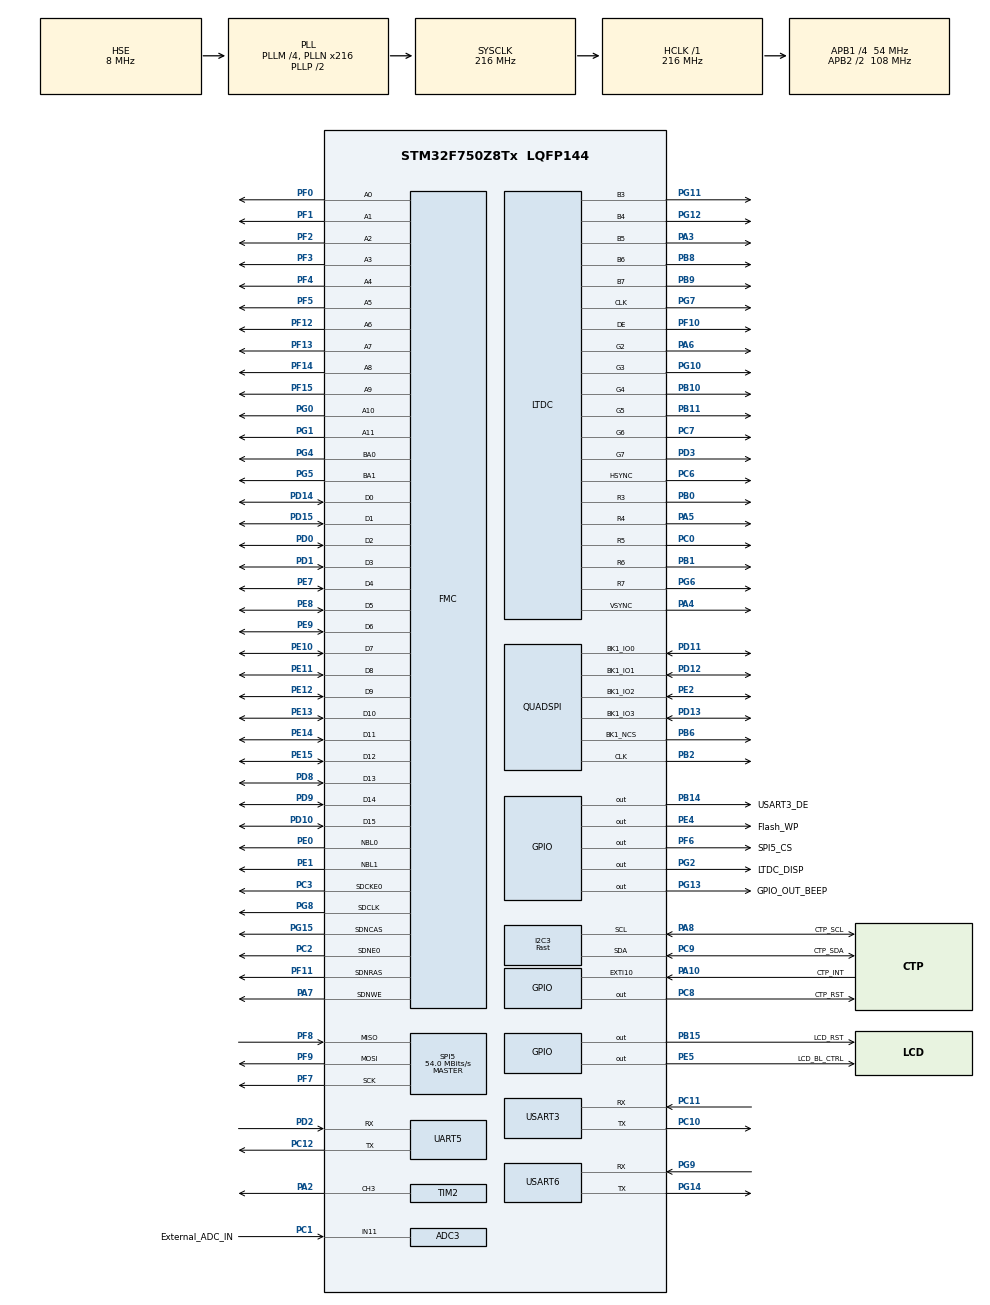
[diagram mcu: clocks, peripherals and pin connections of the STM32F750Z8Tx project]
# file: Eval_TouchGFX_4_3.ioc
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ADC3.Channel-1\#ChannelRegularConversion=ADC_CHANNEL_11
ADC3.NbrOfConversionFlag=1
ADC3.Rank-1\#ChannelRegularConversion=1
ADC3.SamplingTime-1\#ChannelRegularConversion=ADC_SAMPLETIME_3CYCLES
CORTEX_M7.ART_ACCLERATOR_ENABLE=1
CORTEX_M7.AccessPermission-Cortex_Memory_Protection_Unit_Region0_Settings=MPU_REGION_FULL_ACCESS
CORTEX_M7.BaseAddress-Cortex_Memory_Protection_Unit_Region0_Settings=0xC0000000
CORTEX_M7.CPU_DCache=Enabled
CORTEX_M7.CPU_ICache=Enabled
CORTEX_M7.DisableExec-Cortex_Memory_Protection_Unit_Region0_Settings=MPU_INSTRUCTION_ACCESS_DISABLE
CORTEX_M7.Enable-Cortex_Memory_Protection_Unit_Region0_Settings=MPU_REGION_ENABLE
CORTEX_M7.IsCacheable-Cortex_Memory_Protection_Unit_Region0_Settings=MPU_ACCESS_CACHEABLE
CORTEX_M7.IsShareable-Cortex_Memory_Protection_Unit_Region0_Settings=MPU_ACCESS_NOT_SHAREABLE
CORTEX_M7.MPU_Control=MPU_PRIVILEGED_DEFAULT
CORTEX_M7.Size-Cortex_Memory_Protection_Unit_Region0_Settings=MPU_REGION_SIZE_8MB
DMA2D.ColorMode=DMA2D_OUTPUT_RGB565
Dma.MEMTOMEM.1.Direction=DMA_MEMORY_TO_MEMORY
Dma.MEMTOMEM.1.FIFOMode=DMA_FIFOMODE_ENABLE
Dma.MEMTOMEM.1.FIFOThreshold=DMA_FIFO_THRESHOLD_FULL
Dma.MEMTOMEM.1.Instance=DMA2_Stream0
Dma.MEMTOMEM.1.MemBurst=DMA_MBURST_SINGLE
Dma.MEMTOMEM.1.MemDataAlignment=DMA_MDATAALIGN_BYTE
Dma.MEMTOMEM.1.MemInc=DMA_MINC_ENABLE
Dma.MEMTOMEM.1.Mode=DMA_NORMAL
Dma.MEMTOMEM.1.PeriphBurst=DMA_PBURST_SINGLE
Dma.MEMTOMEM.1.PeriphDataAlignment=DMA_PDATAALIGN_BYTE
Dma.MEMTOMEM.1.PeriphInc=DMA_PINC_ENABLE
Dma.MEMTOMEM.1.Priority=DMA_PRIORITY_LOW
Dma.QUADSPI.0.Direction=DMA_PERIPH_TO_MEMORY
Dma.QUADSPI.0.FIFOMode=DMA_FIFOMODE_DISABLE
Dma.QUADSPI.0.Instance=DMA2_Stream7
Dma.QUADSPI.0.MemDataAlignment=DMA_MDATAALIGN_BYTE
Dma.QUADSPI.0.MemInc=DMA_MINC_ENABLE
Dma.QUADSPI.0.Mode=DMA_NORMAL
Dma.QUADSPI.0.PeriphDataAlignment=DMA_PDATAALIGN_BYTE
Dma.QUADSPI.0.PeriphInc=DMA_PINC_DISABLE
Dma.QUADSPI.0.Priority=DMA_PRIORITY_HIGH
Dma.Request0=QUADSPI
Dma.Request1=MEMTOMEM
Dma.Request2=SPI5_RX
Dma.Request3=SPI5_TX
Dma.Request4=USART3_RX
Dma.Request5=USART3_TX
Dma.SPI5_RX.2.Direction=DMA_PERIPH_TO_MEMORY
Dma.SPI5_RX.2.FIFOMode=DMA_FIFOMODE_DISABLE
Dma.SPI5_RX.2.Instance=DMA2_Stream3
Dma.SPI5_RX.2.MemDataAlignment=DMA_MDATAALIGN_BYTE
Dma.SPI5_RX.2.MemInc=DMA_MINC_ENABLE
Dma.SPI5_RX.2.Mode=DMA_NORMAL
Dma.SPI5_RX.2.PeriphDataAlignment=DMA_PDATAALIGN_BYTE
Dma.SPI5_RX.2.PeriphInc=DMA_PINC_DISABLE
Dma.SPI5_RX.2.Priority=DMA_PRIORITY_LOW
Dma.SPI5_TX.3.Direction=DMA_MEMORY_TO_PERIPH
Dma.SPI5_TX.3.FIFOMode=DMA_FIFOMODE_DISABLE
Dma.SPI5_TX.3.Instance=DMA2_Stream4
Dma.SPI5_TX.3.MemDataAlignment=DMA_MDATAALIGN_BYTE
Dma.SPI5_TX.3.MemInc=DMA_MINC_ENABLE
Dma.SPI5_TX.3.Mode=DMA_NORMAL
Dma.SPI5_TX.3.PeriphDataAlignment=DMA_PDATAALIGN_BYTE
Dma.SPI5_TX.3.PeriphInc=DMA_PINC_DISABLE
Dma.SPI5_TX.3.Priority=DMA_PRIORITY_LOW
Dma.USART3_RX.4.Direction=DMA_PERIPH_TO_MEMORY
Dma.USART3_RX.4.FIFOMode=DMA_FIFOMODE_DISABLE
Dma.USART3_RX.4.Instance=DMA1_Stream1
Dma.USART3_RX.4.MemDataAlignment=DMA_MDATAALIGN_BYTE
Dma.USART3_RX.4.MemInc=DMA_MINC_ENABLE
Dma.USART3_RX.4.Mode=DMA_NORMAL
Dma.USART3_RX.4.PeriphDataAlignment=DMA_PDATAALIGN_BYTE
Dma.USART3_RX.4.PeriphInc=DMA_PINC_DISABLE
Dma.USART3_RX.4.Priority=DMA_PRIORITY_HIGH
Dma.USART3_TX.5.Direction=DMA_MEMORY_TO_PERIPH
Dma.USART3_TX.5.FIFOMode=DMA_FIFOMODE_DISABLE
Dma.USART3_TX.5.Instance=DMA1_Stream3
Dma.USART3_TX.5.MemDataAlignment=DMA_MDATAALIGN_BYTE
Dma.USART3_TX.5.MemInc=DMA_MINC_ENABLE
Dma.USART3_TX.5.Mode=DMA_NORMAL
Dma.USART3_TX.5.PeriphDataAlignment=DMA_PDATAALIGN_BYTE
Dma.USART3_TX.5.PeriphInc=DMA_PINC_DISABLE
Dma.USART3_TX.5.Priority=DMA_PRIORITY_LOW
FMC.CASLatency1=FMC_SDRAM_CAS_LATENCY_3
FMC.ExitSelfRefreshDelay1=7
FMC.LoadToActiveDelay1=2
FMC.RCDDelay1=2
FMC.RPDelay1=2
FMC.RPDelay2=2
FMC.ReadBurst1=FMC_SDRAM_RBURST_ENABLE
FMC.ReadBurst2=FMC_SDRAM_RBURST_ENABLE
FMC.RowCycleDelay1=7
FMC.RowCycleDelay2=7
FMC.SDClockPeriod1=FMC_SDRAM_CLOCK_PERIOD_2
FMC.SDClockPeriod2=FMC_SDRAM_CLOCK_PERIOD_2
FMC.SelfRefreshTime1=4
FMC.WriteRecoveryTime1=3
FREERTOS.INCLUDE_vTaskDelayUntil=1
FREERTOS.INCLUDE_xSemaphoreGetMutexHolder=1
FREERTOS.Tasks01=TouchGFXTask,24,8192,TouchGFX_Task,As weak,NULL,Dynamic,NULL,NULL
FREERTOS.configTOTAL_HEAP_SIZE=65536
FREERTOS.configUSE_APPLICATION_TASK_TAG=1
FREERTOS.configUSE_IDLE_HOOK=1
FREERTOS.configUSE_TICK_HOOK=0
I2C3.I2C_Speed_Mode=I2C_Fast
I2C3.Timing=0x6000030D
LTDC.ActiveH=272
LTDC.ActiveW=480
LTDC.Alpha_L0=255
LTDC.DEPolarity=LTDC_DEPOLARITY_AH
LTDC.FBStartAdress_L0=0xC0700000
LTDC.HBP=40
LTDC.HFP=8
LTDC.HSync=4
LTDC.ImageHeight_L0=272
LTDC.ImageWidth_L0=480
LTDC.Layers=0
LTDC.PCPolarity=LTDC_PCPOLARITY_IIPC
LTDC.PixelFormat_L0=LTDC_PIXEL_FORMAT_RGB565
LTDC.VBP=8
LTDC.VFP=8
LTDC.VSync=4
LTDC.WindowX1_L0=480
LTDC.WindowY1_L0=272
Mcu.Family=STM32F7
Mcu.Name=STM32F750Z8Tx
Mcu.Package=LQFP144
NVIC.DMA1_Stream1_IRQn=true\:5\:0\:true\:false\:true\:true\:false\:true
NVIC.DMA1_Stream3_IRQn=true\:5\:0\:true\:false\:true\:true\:false\:true
NVIC.DMA2_Stream3_IRQn=true\:5\:0\:true\:false\:true\:true\:false\:true
NVIC.DMA2_Stream4_IRQn=true\:5\:0\:true\:false\:true\:true\:false\:true
NVIC.DMA2_Stream7_IRQn=true\:5\:0\:true\:false\:true\:true\:false\:true
NVIC.I2C3_ER_IRQn=true\:5\:0\:true\:false\:true\:true\:true\:true
NVIC.I2C3_EV_IRQn=true\:5\:0\:true\:false\:true\:true\:true\:true
NVIC.LTDC_ER_IRQn=true\:5\:0\:true\:false\:true\:true\:true\:true
NVIC.LTDC_IRQn=true\:5\:0\:true\:false\:true\:true\:true\:true
NVIC.PriorityGroup=NVIC_PRIORITYGROUP_4
NVIC.TIM5_IRQn=true\:0\:0\:false\:false\:true\:false\:false\:true
NVIC.TIM7_IRQn=true\:5\:0\:true\:false\:true\:false\:true\:true
NVIC.TimeBase=TIM5_IRQn
NVIC.TimeBaseIP=TIM5
NVIC.USART3_IRQn=true\:5\:0\:true\:false\:true\:true\:true\:true
PA1.Signal=LTDC_R2
PA10.GPIO_Label=CTP_INT
PA10.Signal=GPXTI10
PA13.Mode=Serial_Wire
PA13.Signal=SYS_JTMS-SWDIO
PA14.Mode=Serial_Wire
PA14.Signal=SYS_JTCK-SWCLK
PA2.Signal=S_TIM2_CH3
PA3.GPIO_Speed=GPIO_SPEED_FREQ_VERY_HIGH
PA3.Mode=RGB565
PA3.Signal=LTDC_B5
PA4.GPIO_Speed=GPIO_SPEED_FREQ_VERY_HIGH
PA4.Mode=RGB565
PA4.Signal=LTDC_VSYNC
PA5.GPIO_Speed=GPIO_SPEED_FREQ_VERY_HIGH
PA5.Mode=RGB565
PA5.Signal=LTDC_R4
PA6.GPIO_Speed=GPIO_SPEED_FREQ_VERY_HIGH
PA6.Mode=RGB565
PA6.Signal=LTDC_G2
PA7.Signal=FMC_SDNWE
PA8.GPIO_Label=CTP_SCL
PA8.Mode=I2C
PA8.Signal=I2C3_SCL
PB0.GPIO_Speed=GPIO_SPEED_FREQ_VERY_HIGH
PB0.Mode=RGB565
PB0.Signal=LTDC_R3
PB1.GPIO_Speed=GPIO_SPEED_FREQ_VERY_HIGH
PB1.Mode=RGB565
PB1.Signal=LTDC_R6
PB10.GPIO_Speed=GPIO_SPEED_FREQ_VERY_HIGH
PB10.Mode=RGB565
PB10.Signal=LTDC_G4
PB11.GPIO_Speed=GPIO_SPEED_FREQ_VERY_HIGH
PB11.Mode=RGB565
PB11.Signal=LTDC_G5
PB13.Signal=CAN2_TX
PB14.GPIO_Label=USART3_DE
PB14.Signal=GPIO_Output
PB15.GPIO_Label=LCD_RST
PB15.Signal=GPIO_Output
PB2.Mode=Single Bank 1
PB2.Signal=QUADSPI_CLK
PB6.Mode=Single Bank 1
PB6.Signal=QUADSPI_BK1_NCS
PB8.GPIO_Speed=GPIO_SPEED_FREQ_VERY_HIGH
PB8.Mode=RGB565
PB8.Signal=LTDC_B6
PB9.GPIO_Speed=GPIO_SPEED_FREQ_VERY_HIGH
PB9.Mode=RGB565
PB9.Signal=LTDC_B7
PC0.GPIO_Speed=GPIO_SPEED_FREQ_VERY_HIGH
PC0.Mode=RGB565
PC0.Signal=LTDC_R5
PC1.GPIO_Label=External_ADC_IN
PC1.Signal=ADCx_IN11
PC10.Mode=Asynchronous
PC10.Signal=USART3_TX
PC11.Mode=Asynchronous
PC11.Signal=USART3_RX
PC12.Mode=Asynchronous
PC12.Signal=UART5_TX
PC14/OSC32_IN.Mode=LSE-External-Oscillator
PC14/OSC32_IN.Signal=RCC_OSC32_IN
PC15/OSC32_OUT.Mode=LSE-External-Oscillator
PC15/OSC32_OUT.Signal=RCC_OSC32_OUT
PC2.Mode=SdramChipSelect1_1
PC2.Signal=FMC_SDNE0
PC3.Mode=SdramChipSelect1_1
PC3.Signal=FMC_SDCKE0
PC6.GPIO_Speed=GPIO_SPEED_FREQ_VERY_HIGH
PC6.Mode=RGB565
PC6.Signal=LTDC_HSYNC
PC7.GPIO_Speed=GPIO_SPEED_FREQ_VERY_HIGH
PC7.Mode=RGB565
PC7.Signal=LTDC_G6
PC8.GPIO_Label=CTP_RST
PC8.PinState=GPIO_PIN_SET
PC8.Signal=GPIO_Output
PC9.GPIO_Label=CTP_SDA
PC9.Mode=I2C
PC9.Signal=I2C3_SDA
PD0.Signal=FMC_D2_DA2
PD1.Signal=FMC_D3_DA3
PD10.Signal=FMC_D15_DA15
PD11.Mode=Single Bank 1
PD11.Signal=QUADSPI_BK1_IO0
PD12.Mode=Single Bank 1
PD12.Signal=QUADSPI_BK1_IO1
PD13.Mode=Single Bank 1
PD13.Signal=QUADSPI_BK1_IO3
PD14.Signal=FMC_D0_DA0
PD15.Signal=FMC_D1_DA1
PD2.Mode=Asynchronous
PD2.Signal=UART5_RX
PD3.GPIO_Speed=GPIO_SPEED_FREQ_VERY_HIGH
PD3.Mode=RGB565
PD3.Signal=LTDC_G7
PD6.Signal=LTDC_B2
PD8.Signal=FMC_D13_DA13
PD9.Signal=FMC_D14_DA14
PE0.Signal=FMC_NBL0
PE1.Signal=FMC_NBL1
PE10.Signal=FMC_D7_DA7
PE11.Signal=FMC_D8_DA8
PE12.Signal=FMC_D9_DA9
PE13.Signal=FMC_D10_DA10
PE14.Signal=FMC_D11_DA11
PE15.Signal=FMC_D12_DA12
PE2.Mode=Single Bank 1
PE2.Signal=QUADSPI_BK1_IO2
PE4.GPIO_Label=Flash_WP
PE4.PinState=GPIO_PIN_SET
PE4.Signal=GPIO_Output
PE5.GPIO_Label=LCD_BL_CTRL
PE5.PinState=GPIO_PIN_SET
PE5.Signal=GPIO_Output
PE7.Signal=FMC_D4_DA4
PE8.Signal=FMC_D5_DA5
PE9.Signal=FMC_D6_DA6
PF0.Signal=FMC_A0
PF1.Signal=FMC_A1
PF10.GPIO_PuPd=GPIO_NOPULL
PF10.GPIO_Speed=GPIO_SPEED_FREQ_VERY_HIGH
PF10.Mode=RGB565
PF10.Signal=LTDC_DE
PF11.Signal=FMC_SDNRAS
PF12.Signal=FMC_A6
PF13.Signal=FMC_A7
PF14.Signal=FMC_A8
PF15.Signal=FMC_A9
PF2.Signal=FMC_A2
PF3.Signal=FMC_A3
PF4.Signal=FMC_A4
PF5.Signal=FMC_A5
PF6.GPIO_Label=SPI5_CS
PF6.GPIO_Speed=GPIO_SPEED_FREQ_HIGH
PF6.Signal=GPIO_Output
PF7.Mode=Full_Duplex_Master
PF7.Signal=SPI5_SCK
PF8.Mode=Full_Duplex_Master
PF8.Signal=SPI5_MISO
PF9.Mode=Full_Duplex_Master
PF9.Signal=SPI5_MOSI
PG0.Signal=FMC_A10
PG1.Signal=FMC_A11
PG10.GPIO_Speed=GPIO_SPEED_FREQ_VERY_HIGH
PG10.Mode=RGB565
PG10.Signal=LTDC_G3
PG11.GPIO_Speed=GPIO_SPEED_FREQ_VERY_HIGH
PG11.Mode=RGB565
PG11.Signal=LTDC_B3
PG12.GPIO_Speed=GPIO_SPEED_FREQ_VERY_HIGH
PG12.Mode=RGB565
PG12.Signal=LTDC_B4
PG13.GPIO_Label=GPIO_OUT_BEEP
PG13.Signal=GPIO_Output
PG14.Mode=Asynchronous
PG14.Signal=USART6_TX
PG15.Signal=FMC_SDNCAS
PG2.GPIO_Label=LTDC_DISP
PG2.Signal=GPIO_Output
PG4.Signal=FMC_A14_BA0
PG5.Signal=FMC_A15_BA1
PG6.GPIO_Speed=GPIO_SPEED_FREQ_VERY_HIGH
PG6.Mode=RGB565
PG6.Signal=LTDC_R7
PG7.GPIO_Speed=GPIO_SPEED_FREQ_VERY_HIGH
PG7.Mode=RGB565
PG7.Signal=LTDC_CLK
PG8.Signal=FMC_SDCLK
PG9.Mode=Asynchronous
PG9.Signal=USART6_RX
PH0/OSC_IN.Mode=HSE-External-Oscillator
PH0/OSC_IN.Signal=RCC_OSC_IN
PH1/OSC_OUT.Mode=HSE-External-Oscillator
PH1/OSC_OUT.Signal=RCC_OSC_OUT
ProjectManager.HeapSize=0x1000
ProjectManager.StackSize=0x1000
ProjectManager.TargetToolchain=STM32CubeIDE
QUADSPI.ChipSelectHighTime=QSPI_CS_HIGH_TIME_2_CYCLE
QUADSPI.ClockPrescaler=3
QUADSPI.FifoThreshold=4
QUADSPI.FlashSize=16
QUADSPI.SampleShifting=QSPI_SAMPLE_SHIFTING_HALFCYCLE
RCC.AHBFreq_Value=216000000
RCC.APB1CLKDivider=RCC_HCLK_DIV4
RCC.APB1Freq_Value=54000000
RCC.APB1TimFreq_Value=108000000
RCC.APB2CLKDivider=RCC_HCLK_DIV2
RCC.APB2Freq_Value=108000000
RCC.APB2TimFreq_Value=216000000
RCC.CortexFreq_Value=216000000
RCC.HCLKFreq_Value=216000000
RCC.HSE_VALUE=8000000
RCC.HSI_VALUE=16000000
RCC.LSE_Drive_Capability=RCC_LSEDRIVE_HIGH
RCC.PLLM=4
RCC.PLLN=216
RCC.PLLSAIN=54
RCC.PLLSAIR=3
RCC.PLLSAIRDiv=RCC_PLLSAIDIVR_4
RCC.PLLSourceVirtual=RCC_PLLSOURCE_HSE
RCC.RTCClockSelection=RCC_RTCCLKSOURCE_LSE
RCC.SYSCLKFreq_VALUE=216000000
RCC.SYSCLKSource=RCC_SYSCLKSOURCE_PLLCLK
RCC.USBFreq_Value=216000000
RCC.VCOOutputFreq_Value=432000000
RTC.Format=RTC_FORMAT_BIN
RTC.WeekDay=RTC_WEEKDAY_FRIDAY
RTC.Year=21
SH.ADCx_IN11.0=ADC3_IN11,IN11
SH.FMC_A0.0=FMC_A0,12b-sda1
SH.FMC_A1.0=FMC_A1,12b-sda1
SH.FMC_A10.0=FMC_A10,12b-sda1
SH.FMC_A11.0=FMC_A11,12b-sda1
SH.FMC_A14_BA0.0=FMC_BA0,FourSdramBanks1
SH.FMC_A15_BA1.0=FMC_BA1,FourSdramBanks1
SH.FMC_A2.0=FMC_A2,12b-sda1
SH.FMC_A3.0=FMC_A3,12b-sda1
SH.FMC_A4.0=FMC_A4,12b-sda1
SH.FMC_A5.0=FMC_A5,12b-sda1
SH.FMC_A6.0=FMC_A6,12b-sda1
SH.FMC_A7.0=FMC_A7,12b-sda1
SH.FMC_A8.0=FMC_A8,12b-sda1
SH.FMC_A9.0=FMC_A9,12b-sda1
SH.FMC_D0_DA0.0=FMC_D0,sd-16b-d1
SH.FMC_D10_DA10.0=FMC_D10,sd-16b-d1
SH.FMC_D11_DA11.0=FMC_D11,sd-16b-d1
SH.FMC_D12_DA12.0=FMC_D12,sd-16b-d1
SH.FMC_D13_DA13.0=FMC_D13,sd-16b-d1
SH.FMC_D14_DA14.0=FMC_D14,sd-16b-d1
SH.FMC_D15_DA15.0=FMC_D15,sd-16b-d1
SH.FMC_D1_DA1.0=FMC_D1,sd-16b-d1
SH.FMC_D2_DA2.0=FMC_D2,sd-16b-d1
SH.FMC_D3_DA3.0=FMC_D3,sd-16b-d1
SH.FMC_D4_DA4.0=FMC_D4,sd-16b-d1
SH.FMC_D5_DA5.0=FMC_D5,sd-16b-d1
SH.FMC_D6_DA6.0=FMC_D6,sd-16b-d1
SH.FMC_D7_DA7.0=FMC_D7,sd-16b-d1
SH.FMC_D8_DA8.0=FMC_D8,sd-16b-d1
SH.FMC_D9_DA9.0=FMC_D9,sd-16b-d1
SH.FMC_NBL0.0=FMC_NBL0,Sd2ByteEnable1
SH.FMC_NBL1.0=FMC_NBL1,Sd2ByteEnable1
SH.FMC_SDCLK.0=FMC_SDCLK,12b-sda1
SH.FMC_SDNCAS.0=FMC_SDNCAS,12b-sda1
SH.FMC_SDNRAS.0=FMC_SDNRAS,12b-sda1
SH.FMC_SDNWE.0=FMC_SDNWE,12b-sda1
SH.S_TIM2_CH3.0=TIM2_CH3,PWM Generation3 CH3
SPI5.CalculateBaudRate=54.0 MBits/s
SPI5.DataSize=SPI_DATASIZE_8BIT
SPI5.Direction=SPI_DIRECTION_2LINES
SPI5.Mode=SPI_MODE_MASTER
SPI5.NSSPMode=SPI_NSS_PULSE_DISABLE
SPI5.VirtualType=VM_MASTER
STMicroelectronics.X-CUBE-TOUCHGFX.4.16.0.ApplicationCcGraphicsJjApplication=TouchGFXOoGenerator
STMicroelectronics.X-CUBE-TOUCHGFX.4.16.0.tgfx_address1=0xc0700000
STMicroelectronics.X-CUBE-TOUCHGFX.4.16.0.tgfx_address2=0xc073FC00
STMicroelectronics.X-CUBE-TOUCHGFX.4.16.0.tgfx_buffering_strategy=Double
STMicroelectronics.X-CUBE-TOUCHGFX.4.16.0.tgfx_custom_height=128
STMicroelectronics.X-CUBE-TOUCHGFX.4.16.0.tgfx_display_interface=disp_ltdc
STMicroelectronics.X-CUBE-TOUCHGFX.4.16.0.tgfx_hardware_accelerator=dma_2d
STMicroelectronics.X-CUBE-TOUCHGFX.4.16.0.tgfx_location=By Address
STMicroelectronics.X-CUBE-TOUCHGFX.4.16.0.tgfx_vsync=vsync_ltdc
TIM2.AutoReloadPreload=TIM_AUTORELOAD_PRELOAD_ENABLE
TIM2.Channel-PWM\ Generation3\ CH3=TIM_CHANNEL_3
TIM2.Period=99
TIM2.Prescaler=72
TIM7.Period=0
USART3.VirtualMode-Asynchronous=VM_ASYNC
USART6.VirtualMode-Asynchronous=VM_ASYNC
VP_CRC_VS_CRC.Mode=CRC_Activate
VP_DMA2D_VS_DMA2D.Mode=DMA2D_Activate
VP_FREERTOS_VS_CMSIS_V2.Mode=CMSIS_V2
VP_RTC_VS_RTC_Activate.Mode=RTC_Enabled
VP_RTC_VS_RTC_Calendar.Mode=RTC_Calendar
VP_STMicroelectronics.X-CUBE-TOUCHGFX_VS_GraphicsJjApplication_4.16.0.Mode=GraphicsJjApplication
VP_SYS_VS_tim5.Mode=TIM5
VP_TIM7_VS_ClockSourceINT.Mode=Enable_Timer
board=custom

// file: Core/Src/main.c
/* USER CODE BEGIN Header */
/**
  ******************************************************************************
  * @file           : main.c
  * @brief          : Main program body
  ******************************************************************************
  * @attention
  *
  * <h2><center>&copy; Copyright (c) 2020 STMicroelectronics.
  * All rights reserved.</center></h2>
  *
  * This software component is licensed by ST under Ultimate Liberty license
  * SLA0044, the "License"; You may not use this file except in compliance with
  * the License. You may obtain a copy of the License at:
  *                             www.st.com/SLA0044
  *
  ******************************************************************************
  */
/* USER CODE END Header */
#include "main.h"
#include "cmsis_os.h"
#include "app_touchgfx.h"

/* USER CODE BEGIN Includes */
#include "stm32f7508_discovery_sdram.h"
/* USER CODE END Includes */

/* USER CODE BEGIN PD */
#define ADDR_DISPLAY_MEM    ((uint32_t)0xC0700000)
/* USER CODE END PD */

ADC_HandleTypeDef hadc3;

CRC_HandleTypeDef hcrc;

DMA2D_HandleTypeDef hdma2d;

I2C_HandleTypeDef hi2c3;

LTDC_HandleTypeDef hltdc;

QSPI_HandleTypeDef hqspi;
DMA_HandleTypeDef hdma_quadspi;

RTC_HandleTypeDef hrtc;

SPI_HandleTypeDef hspi5;
DMA_HandleTypeDef hdma_spi5_rx;
DMA_HandleTypeDef hdma_spi5_tx;

TIM_HandleTypeDef htim2;
TIM_HandleTypeDef htim7;

UART_HandleTypeDef huart5;
UART_HandleTypeDef huart3;
UART_HandleTypeDef huart6;
DMA_HandleTypeDef hdma_usart3_rx;
DMA_HandleTypeDef hdma_usart3_tx;

DMA_HandleTypeDef hdma_memtomem_dma2_stream0;
SDRAM_HandleTypeDef hsdram1;

/* Definitions for TouchGFXTask */
osThreadId_t TouchGFXTaskHandle;
const osThreadAttr_t TouchGFXTask_attributes = {
  .name = "TouchGFXTask",
  .priority = (osPriority_t) osPriorityNormal,
  .stack_size = 8192 * 4
};

void SystemClock_Config(void);
static void MPU_Config(void);
static void MX_GPIO_Init(void);
static void MX_DMA_Init(void);
static void MX_QUADSPI_Init(void);
static void MX_DMA2D_Init(void);
static void MX_LTDC_Init(void);
static void MX_CRC_Init(void);
static void MX_FMC_Init(void);
static void MX_TIM7_Init(void);
static void MX_USART3_UART_Init(void);
static void MX_ADC3_Init(void);
static void MX_SPI5_Init(void);
static void MX_USART6_UART_Init(void);
static void MX_UART5_Init(void);
static void MX_I2C3_Init(void);
static void MX_TIM2_Init(void);
static void MX_RTC_Init(void);
void TouchGFX_Task(void *argument);

/* USER CODE BEGIN PFP */
void MX_SDRAM_InitEx(void);
/* USER CODE END PFP */

/* USER CODE BEGIN 0 */
void Debug()
{
  while(1){

    HAL_Delay(500);

    HAL_GPIO_WritePin(GPIOE, LCD_BL_CTRL_Pin, GPIO_PIN_SET);

    HAL_Delay(500);

    HAL_GPIO_WritePin(GPIOE, LCD_BL_CTRL_Pin, GPIO_PIN_RESET);

  }

}

void HW_VerifySDRAM(void)
{
  volatile uint32_t *pBuf = (uint32_t*) 0xc0000000;

  static uint32_t failCnt = 0;
  uint32_t cnt = 8 * 1024 * 1024 / 4;

  for (uint32_t i = 0; i < cnt; i++)
    *(pBuf++) = i;

  pBuf = (uint32_t*) 0xc0000000;

  for (uint32_t i = 0; i < cnt; i++) {

    if (*(pBuf++) != i) {

      failCnt++;
      HAL_GPIO_WritePin(GPIOE, LCD_BL_CTRL_Pin, GPIO_PIN_SET);
      while(1);
    }
  }

}

/* USER CODE END 0 */

int main(void)
{

  /* MPU Configuration--------------------------------------------------------*/
  MPU_Config();

  /* Enable I-Cache---------------------------------------------------------*/
  SCB_EnableICache();

  /* Enable D-Cache---------------------------------------------------------*/
  SCB_EnableDCache();

  /* MCU Configuration--------------------------------------------------------*/

  /* Reset of all peripherals, Initializes the Flash interface and the Systick. */
  HAL_Init();

  /* Configure the system clock */
  SystemClock_Config();

  /* Initialize all configured peripherals */
  MX_GPIO_Init();
  MX_DMA_Init();
  MX_QUADSPI_Init();
  MX_DMA2D_Init();
  MX_LTDC_Init();
  MX_CRC_Init();
  MX_FMC_Init();
  MX_TIM7_Init();
  MX_USART3_UART_Init();
  MX_ADC3_Init();
  MX_SPI5_Init();
  MX_USART6_UART_Init();
  MX_UART5_Init();
  MX_I2C3_Init();
  MX_TIM2_Init();
  MX_RTC_Init();
  MX_TouchGFX_Init();

  /* Init scheduler */
  osKernelInitialize();

  /* Create the thread(s) */
  /* creation of TouchGFXTask */
  TouchGFXTaskHandle = osThreadNew(TouchGFX_Task, NULL, &TouchGFXTask_attributes);

  /* Start scheduler */
  osKernelStart();

  /* We should never get here as control is now taken by the scheduler */
  /* Infinite loop */
  while (1)
  {

  }
}

void SystemClock_Config(void)
{
  RCC_OscInitTypeDef RCC_OscInitStruct = {0};
  RCC_ClkInitTypeDef RCC_ClkInitStruct = {0};
  RCC_PeriphCLKInitTypeDef PeriphClkInitStruct = {0};

  /** Configure LSE Drive Capability
  */
  HAL_PWR_EnableBkUpAccess();
  __HAL_RCC_LSEDRIVE_CONFIG(RCC_LSEDRIVE_HIGH);
  /** Configure the main internal regulator output voltage
  */
  __HAL_RCC_PWR_CLK_ENABLE();
  __HAL_PWR_VOLTAGESCALING_CONFIG(PWR_REGULATOR_VOLTAGE_SCALE1);
  /** Initializes the RCC Oscillators according to the specified parameters
  * in the RCC_OscInitTypeDef structure.
  */
  RCC_OscInitStruct.OscillatorType = RCC_OSCILLATORTYPE_HSE|RCC_OSCILLATORTYPE_LSE;
  RCC_OscInitStruct.HSEState = RCC_HSE_ON;
  RCC_OscInitStruct.LSEState = RCC_LSE_ON;
  RCC_OscInitStruct.PLL.PLLState = RCC_PLL_ON;
  RCC_OscInitStruct.PLL.PLLSource = RCC_PLLSOURCE_HSE;
  RCC_OscInitStruct.PLL.PLLM = 4;
  RCC_OscInitStruct.PLL.PLLN = 216;
  RCC_OscInitStruct.PLL.PLLP = RCC_PLLP_DIV2;
  RCC_OscInitStruct.PLL.PLLQ = 2;
  if (HAL_RCC_OscConfig(&RCC_OscInitStruct) != HAL_OK)
  {
    Error_Handler();
  }
  /** Activate the Over-Drive mode
  */
  if (HAL_PWREx_EnableOverDrive() != HAL_OK)
  {
    Error_Handler();
  }
  /** Initializes the CPU, AHB and APB buses clocks
  */
  RCC_ClkInitStruct.ClockType = RCC_CLOCKTYPE_HCLK|RCC_CLOCKTYPE_SYSCLK
                              |RCC_CLOCKTYPE_PCLK1|RCC_CLOCKTYPE_PCLK2;
  RCC_ClkInitStruct.SYSCLKSource = RCC_SYSCLKSOURCE_PLLCLK;
  RCC_ClkInitStruct.AHBCLKDivider = RCC_SYSCLK_DIV1;
  RCC_ClkInitStruct.APB1CLKDivider = RCC_HCLK_DIV4;
  RCC_ClkInitStruct.APB2CLKDivider = RCC_HCLK_DIV2;

  if (HAL_RCC_ClockConfig(&RCC_ClkInitStruct, FLASH_LATENCY_7) != HAL_OK)
  {
    Error_Handler();
  }
  PeriphClkInitStruct.PeriphClockSelection = RCC_PERIPHCLK_LTDC|RCC_PERIPHCLK_RTC
                              |RCC_PERIPHCLK_USART3|RCC_PERIPHCLK_USART6
                              |RCC_PERIPHCLK_UART5|RCC_PERIPHCLK_I2C3;
  PeriphClkInitStruct.PLLSAI.PLLSAIN = 54;
  PeriphClkInitStruct.PLLSAI.PLLSAIR = 3;
  PeriphClkInitStruct.PLLSAI.PLLSAIQ = 2;
  PeriphClkInitStruct.PLLSAI.PLLSAIP = RCC_PLLSAIP_DIV2;
  PeriphClkInitStruct.PLLSAIDivQ = 1;
  PeriphClkInitStruct.PLLSAIDivR = RCC_PLLSAIDIVR_4;
  PeriphClkInitStruct.RTCClockSelection = RCC_RTCCLKSOURCE_LSE;
  PeriphClkInitStruct.Usart3ClockSelection = RCC_USART3CLKSOURCE_PCLK1;
  PeriphClkInitStruct.Uart5ClockSelection = RCC_UART5CLKSOURCE_PCLK1;
  PeriphClkInitStruct.Usart6ClockSelection = RCC_USART6CLKSOURCE_PCLK2;
  PeriphClkInitStruct.I2c3ClockSelection = RCC_I2C3CLKSOURCE_PCLK1;
  if (HAL_RCCEx_PeriphCLKConfig(&PeriphClkInitStruct) != HAL_OK)
  {
    Error_Handler();
  }
}

static void MX_ADC3_Init(void)
{

  ADC_ChannelConfTypeDef sConfig = {0};

  /** Configure the global features of the ADC (Clock, Resolution, Data Alignment and number of conversion)
  */
  hadc3.Instance = ADC3;
  hadc3.Init.ClockPrescaler = ADC_CLOCK_SYNC_PCLK_DIV4;
  hadc3.Init.Resolution = ADC_RESOLUTION_12B;
  hadc3.Init.ScanConvMode = ADC_SCAN_DISABLE;
  hadc3.Init.ContinuousConvMode = DISABLE;
  hadc3.Init.DiscontinuousConvMode = DISABLE;
  hadc3.Init.ExternalTrigConvEdge = ADC_EXTERNALTRIGCONVEDGE_NONE;
  hadc3.Init.ExternalTrigConv = ADC_SOFTWARE_START;
  hadc3.Init.DataAlign = ADC_DATAALIGN_RIGHT;
  hadc3.Init.NbrOfConversion = 1;
  hadc3.Init.DMAContinuousRequests = DISABLE;
  hadc3.Init.EOCSelection = ADC_EOC_SINGLE_CONV;
  if (HAL_ADC_Init(&hadc3) != HAL_OK)
  {
    Error_Handler();
  }
  /** Configure for the selected ADC regular channel its corresponding rank in the sequencer and its sample time.
  */
  sConfig.Channel = ADC_CHANNEL_11;
  sConfig.Rank = ADC_REGULAR_RANK_1;
  sConfig.SamplingTime = ADC_SAMPLETIME_3CYCLES;
  if (HAL_ADC_ConfigChannel(&hadc3, &sConfig) != HAL_OK)
  {
    Error_Handler();
  }

}

static void MX_CRC_Init(void)
{

  hcrc.Instance = CRC;
  hcrc.Init.DefaultPolynomialUse = DEFAULT_POLYNOMIAL_ENABLE;
  hcrc.Init.DefaultInitValueUse = DEFAULT_INIT_VALUE_ENABLE;
  hcrc.Init.InputDataInversionMode = CRC_INPUTDATA_INVERSION_NONE;
  hcrc.Init.OutputDataInversionMode = CRC_OUTPUTDATA_INVERSION_DISABLE;
  hcrc.InputDataFormat = CRC_INPUTDATA_FORMAT_BYTES;
  if (HAL_CRC_Init(&hcrc) != HAL_OK)
  {
    Error_Handler();
  }

}

static void MX_DMA2D_Init(void)
{

  hdma2d.Instance = DMA2D;
  hdma2d.Init.Mode = DMA2D_M2M;
  hdma2d.Init.ColorMode = DMA2D_OUTPUT_RGB565;
  hdma2d.Init.OutputOffset = 0;
  hdma2d.LayerCfg[1].InputOffset = 0;
  hdma2d.LayerCfg[1].InputColorMode = DMA2D_INPUT_RGB565;
  hdma2d.LayerCfg[1].AlphaMode = DMA2D_NO_MODIF_ALPHA;
  hdma2d.LayerCfg[1].InputAlpha = 0;
  if (HAL_DMA2D_Init(&hdma2d) != HAL_OK)
  {
    Error_Handler();
  }
  if (HAL_DMA2D_ConfigLayer(&hdma2d, 1) != HAL_OK)
  {
    Error_Handler();
  }

}

static void MX_I2C3_Init(void)
{

  hi2c3.Instance = I2C3;
  hi2c3.Init.Timing = 0x6000030D;
  hi2c3.Init.OwnAddress1 = 0;
  hi2c3.Init.AddressingMode = I2C_ADDRESSINGMODE_7BIT;
  hi2c3.Init.DualAddressMode = I2C_DUALADDRESS_DISABLE;
  hi2c3.Init.OwnAddress2 = 0;
  hi2c3.Init.OwnAddress2Masks = I2C_OA2_NOMASK;
  hi2c3.Init.GeneralCallMode = I2C_GENERALCALL_DISABLE;
  hi2c3.Init.NoStretchMode = I2C_NOSTRETCH_DISABLE;
  if (HAL_I2C_Init(&hi2c3) != HAL_OK)
  {
    Error_Handler();
  }
  /** Configure Analogue filter
  */
  if (HAL_I2CEx_ConfigAnalogFilter(&hi2c3, I2C_ANALOGFILTER_ENABLE) != HAL_OK)
  {
    Error_Handler();
  }
  /** Configure Digital filter
  */
  if (HAL_I2CEx_ConfigDigitalFilter(&hi2c3, 0) != HAL_OK)
  {
    Error_Handler();
  }

}

static void MX_LTDC_Init(void)
{

  LTDC_LayerCfgTypeDef pLayerCfg = {0};
  LTDC_LayerCfgTypeDef pLayerCfg1 = {0};

  hltdc.Instance = LTDC;
  hltdc.Init.HSPolarity = LTDC_HSPOLARITY_AL;
  hltdc.Init.VSPolarity = LTDC_VSPOLARITY_AL;
  hltdc.Init.DEPolarity = LTDC_DEPOLARITY_AH;
  hltdc.Init.PCPolarity = LTDC_PCPOLARITY_IIPC;
  hltdc.Init.HorizontalSync = 3;
  hltdc.Init.VerticalSync = 3;
  hltdc.Init.AccumulatedHBP = 43;
  hltdc.Init.AccumulatedVBP = 11;
  hltdc.Init.AccumulatedActiveW = 523;
  hltdc.Init.AccumulatedActiveH = 283;
  hltdc.Init.TotalWidth = 531;
  hltdc.Init.TotalHeigh = 291;
  hltdc.Init.Backcolor.Blue = 0;
  hltdc.Init.Backcolor.Green = 0;
  hltdc.Init.Backcolor.Red = 0;
  if (HAL_LTDC_Init(&hltdc) != HAL_OK)
  {
    Error_Handler();
  }
  pLayerCfg.WindowX0 = 0;
  pLayerCfg.WindowX1 = 480;
  pLayerCfg.WindowY0 = 0;
  pLayerCfg.WindowY1 = 272;
  pLayerCfg.PixelFormat = LTDC_PIXEL_FORMAT_RGB565;
  pLayerCfg.Alpha = 255;
  pLayerCfg.Alpha0 = 0;
  pLayerCfg.BlendingFactor1 = LTDC_BLENDING_FACTOR1_CA;
  pLayerCfg.BlendingFactor2 = LTDC_BLENDING_FACTOR2_CA;
  pLayerCfg.FBStartAdress = 0xC0700000;
  pLayerCfg.ImageWidth = 480;
  pLayerCfg.ImageHeight = 272;
  pLayerCfg.Backcolor.Blue = 0;
  pLayerCfg.Backcolor.Green = 0;
  pLayerCfg.Backcolor.Red = 0;
  if (HAL_LTDC_ConfigLayer(&hltdc, &pLayerCfg, 0) != HAL_OK)
  {
    Error_Handler();
  }
  pLayerCfg1.WindowX0 = 0;
  pLayerCfg1.WindowX1 = 0;
  pLayerCfg1.WindowY0 = 0;
  pLayerCfg1.WindowY1 = 0;
  pLayerCfg1.Alpha = 0;
  pLayerCfg1.Alpha0 = 0;
  pLayerCfg1.BlendingFactor1 = LTDC_BLENDING_FACTOR1_CA;
  pLayerCfg1.BlendingFactor2 = LTDC_BLENDING_FACTOR2_CA;
  pLayerCfg1.FBStartAdress = 0;
  pLayerCfg1.ImageWidth = 0;
  pLayerCfg1.ImageHeight = 0;
  pLayerCfg1.Backcolor.Blue = 0;
  pLayerCfg1.Backcolor.Green = 0;
  pLayerCfg1.Backcolor.Red = 0;
  if (HAL_LTDC_ConfigLayer(&hltdc, &pLayerCfg1, 1) != HAL_OK)
  {
    Error_Handler();
  }
  /* USER CODE BEGIN LTDC_Init 2 */
  HAL_GPIO_WritePin(LCD_RST_GPIO_Port, LCD_RST_Pin, GPIO_PIN_SET);
  HAL_Delay(50);
  HAL_GPIO_WritePin(LCD_RST_GPIO_Port, LCD_RST_Pin, GPIO_PIN_RESET);
  HAL_Delay(100);
  HAL_GPIO_WritePin(LCD_RST_GPIO_Port, LCD_RST_Pin, GPIO_PIN_SET);
  HAL_Delay(50);

  HAL_GPIO_WritePin( LTDC_DISP_GPIO_Port, LTDC_DISP_Pin, GPIO_PIN_SET);
  HAL_GPIO_WritePin(GPIOE, LCD_BL_CTRL_Pin, GPIO_PIN_SET);
  /* USER CODE END LTDC_Init 2 */

}

static void MX_QUADSPI_Init(void)
{

  /* USER CODE BEGIN QUADSPI_Init 0 */
  return;
  /* USER CODE END QUADSPI_Init 0 */

  /* QUADSPI parameter configuration*/
  hqspi.Instance = QUADSPI;
  hqspi.Init.ClockPrescaler = 3;
  hqspi.Init.FifoThreshold = 4;
  hqspi.Init.SampleShifting = QSPI_SAMPLE_SHIFTING_HALFCYCLE;
  hqspi.Init.FlashSize = 16;
  hqspi.Init.ChipSelectHighTime = QSPI_CS_HIGH_TIME_2_CYCLE;
  hqspi.Init.ClockMode = QSPI_CLOCK_MODE_0;
  hqspi.Init.FlashID = QSPI_FLASH_ID_1;
  hqspi.Init.DualFlash = QSPI_DUALFLASH_DISABLE;
  if (HAL_QSPI_Init(&hqspi) != HAL_OK)
  {
    Error_Handler();
  }

}

static void MX_RTC_Init(void)
{

  RTC_TimeTypeDef sTime = {0};
  RTC_DateTypeDef sDate = {0};

  /** Initialize RTC Only
  */
  hrtc.Instance = RTC;
  hrtc.Init.HourFormat = RTC_HOURFORMAT_24;
  hrtc.Init.AsynchPrediv = 127;
  hrtc.Init.SynchPrediv = 255;
  hrtc.Init.OutPut = RTC_OUTPUT_DISABLE;
  hrtc.Init.OutPutPolarity = RTC_OUTPUT_POLARITY_HIGH;
  hrtc.Init.OutPutType = RTC_OUTPUT_TYPE_OPENDRAIN;
  if (HAL_RTC_Init(&hrtc) != HAL_OK)
  {
    Error_Handler();
  }

  /** Initialize RTC and set the Time and Date
  */
  sTime.Hours = 0;
  sTime.Minutes = 0;
  sTime.Seconds = 0;
  sTime.DayLightSaving = RTC_DAYLIGHTSAVING_NONE;
  sTime.StoreOperation = RTC_STOREOPERATION_RESET;
  if (HAL_RTC_SetTime(&hrtc, &sTime, RTC_FORMAT_BIN) != HAL_OK)
  {
    Error_Handler();
  }
  sDate.WeekDay = RTC_WEEKDAY_FRIDAY;
  sDate.Month = RTC_MONTH_JANUARY;
  sDate.Date = 1;
  sDate.Year = 21;

  if (HAL_RTC_SetDate(&hrtc, &sDate, RTC_FORMAT_BIN) != HAL_OK)
  {
    Error_Handler();
  }

}

static void MX_SPI5_Init(void)
{

  /* SPI5 parameter configuration*/
  hspi5.Instance = SPI5;
  hspi5.Init.Mode = SPI_MODE_MASTER;
  hspi5.Init.Direction = SPI_DIRECTION_2LINES;
  hspi5.Init.DataSize = SPI_DATASIZE_8BIT;
  hspi5.Init.CLKPolarity = SPI_POLARITY_LOW;
  hspi5.Init.CLKPhase = SPI_PHASE_1EDGE;
  hspi5.Init.NSS = SPI_NSS_SOFT;
  hspi5.Init.BaudRatePrescaler = SPI_BAUDRATEPRESCALER_2;
  hspi5.Init.FirstBit = SPI_FIRSTBIT_MSB;
  hspi5.Init.TIMode = SPI_TIMODE_DISABLE;
  hspi5.Init.CRCCalculation = SPI_CRCCALCULATION_DISABLE;
  hspi5.Init.CRCPolynomial = 7;
  hspi5.Init.CRCLength = SPI_CRC_LENGTH_DATASIZE;
  hspi5.Init.NSSPMode = SPI_NSS_PULSE_DISABLE;
  if (HAL_SPI_Init(&hspi5) != HAL_OK)
  {
    Error_Handler();
  }

}

static void MX_TIM2_Init(void)
{

  TIM_MasterConfigTypeDef sMasterConfig = {0};
  TIM_OC_InitTypeDef sConfigOC = {0};

  htim2.Instance = TIM2;
  htim2.Init.Prescaler = 72;
  htim2.Init.CounterMode = TIM_COUNTERMODE_UP;
  htim2.Init.Period = 99;
  htim2.Init.ClockDivision = TIM_CLOCKDIVISION_DIV1;
  htim2.Init.AutoReloadPreload = TIM_AUTORELOAD_PRELOAD_ENABLE;
  if (HAL_TIM_PWM_Init(&htim2) != HAL_OK)
  {
    Error_Handler();
  }
  sMasterConfig.MasterOutputTrigger = TIM_TRGO_RESET;
  sMasterConfig.MasterSlaveMode = TIM_MASTERSLAVEMODE_DISABLE;
  if (HAL_TIMEx_MasterConfigSynchronization(&htim2, &sMasterConfig) != HAL_OK)
  {
    Error_Handler();
  }
  sConfigOC.OCMode = TIM_OCMODE_PWM1;
  sConfigOC.Pulse = 0;
  sConfigOC.OCPolarity = TIM_OCPOLARITY_HIGH;
  sConfigOC.OCFastMode = TIM_OCFAST_DISABLE;
  if (HAL_TIM_PWM_ConfigChannel(&htim2, &sConfigOC, TIM_CHANNEL_3) != HAL_OK)
  {
    Error_Handler();
  }
  HAL_TIM_MspPostInit(&htim2);

}

static void MX_TIM7_Init(void)
{

  TIM_MasterConfigTypeDef sMasterConfig = {0};

  htim7.Instance = TIM7;
  htim7.Init.Prescaler = 0;
  htim7.Init.CounterMode = TIM_COUNTERMODE_UP;
  htim7.Init.Period = 0;
  htim7.Init.AutoReloadPreload = TIM_AUTORELOAD_PRELOAD_DISABLE;
  if (HAL_TIM_Base_Init(&htim7) != HAL_OK)
  {
    Error_Handler();
  }
  sMasterConfig.MasterOutputTrigger = TIM_TRGO_RESET;
  sMasterConfig.MasterSlaveMode = TIM_MASTERSLAVEMODE_DISABLE;
  if (HAL_TIMEx_MasterConfigSynchronization(&htim7, &sMasterConfig) != HAL_OK)
  {
    Error_Handler();
  }

}

static void MX_UART5_Init(void)
{

  huart5.Instance = UART5;
  huart5.Init.BaudRate = 115200;
  huart5.Init.WordLength = UART_WORDLENGTH_8B;
  huart5.Init.StopBits = UART_STOPBITS_1;
  huart5.Init.Parity = UART_PARITY_NONE;
  huart5.Init.Mode = UART_MODE_TX_RX;
  huart5.Init.HwFlowCtl = UART_HWCONTROL_NONE;
  huart5.Init.OverSampling = UART_OVERSAMPLING_16;
  huart5.Init.OneBitSampling = UART_ONE_BIT_SAMPLE_DISABLE;
  huart5.AdvancedInit.AdvFeatureInit = UART_ADVFEATURE_NO_INIT;
  if (HAL_UART_Init(&huart5) != HAL_OK)
  {
    Error_Handler();
  }

}

static void MX_USART3_UART_Init(void)
{

  huart3.Instance = USART3;
  huart3.Init.BaudRate = 115200;
  huart3.Init.WordLength = UART_WORDLENGTH_8B;
  huart3.Init.StopBits = UART_STOPBITS_1;
  huart3.Init.Parity = UART_PARITY_NONE;
  huart3.Init.Mode = UART_MODE_TX_RX;
  huart3.Init.HwFlowCtl = UART_HWCONTROL_NONE;
  huart3.Init.OverSampling = UART_OVERSAMPLING_16;
  huart3.Init.OneBitSampling = UART_ONE_BIT_SAMPLE_DISABLE;
  huart3.AdvancedInit.AdvFeatureInit = UART_ADVFEATURE_NO_INIT;
  if (HAL_UART_Init(&huart3) != HAL_OK)
  {
    Error_Handler();
  }

}

static void MX_USART6_UART_Init(void)
{

  huart6.Instance = USART6;
  huart6.Init.BaudRate = 115200;
  huart6.Init.WordLength = UART_WORDLENGTH_8B;
  huart6.Init.StopBits = UART_STOPBITS_1;
  huart6.Init.Parity = UART_PARITY_NONE;
  huart6.Init.Mode = UART_MODE_TX_RX;
  huart6.Init.HwFlowCtl = UART_HWCONTROL_NONE;
  huart6.Init.OverSampling = UART_OVERSAMPLING_16;
  huart6.Init.OneBitSampling = UART_ONE_BIT_SAMPLE_DISABLE;
  huart6.AdvancedInit.AdvFeatureInit = UART_ADVFEATURE_NO_INIT;
  if (HAL_UART_Init(&huart6) != HAL_OK)
  {
    Error_Handler();
  }

}

static void MX_DMA_Init(void)
{

  /* DMA controller clock enable */
  __HAL_RCC_DMA2_CLK_ENABLE();
  __HAL_RCC_DMA1_CLK_ENABLE();

  /* Configure DMA request hdma_memtomem_dma2_stream0 on DMA2_Stream0 */
  hdma_memtomem_dma2_stream0.Instance = DMA2_Stream0;
  hdma_memtomem_dma2_stream0.Init.Channel = DMA_CHANNEL_0;
  hdma_memtomem_dma2_stream0.Init.Direction = DMA_MEMORY_TO_MEMORY;
  hdma_memtomem_dma2_stream0.Init.PeriphInc = DMA_PINC_ENABLE;
  hdma_memtomem_dma2_stream0.Init.MemInc = DMA_MINC_ENABLE;
  hdma_memtomem_dma2_stream0.Init.PeriphDataAlignment = DMA_PDATAALIGN_BYTE;
  hdma_memtomem_dma2_stream0.Init.MemDataAlignment = DMA_MDATAALIGN_BYTE;
  hdma_memtomem_dma2_stream0.Init.Mode = DMA_NORMAL;
  hdma_memtomem_dma2_stream0.Init.Priority = DMA_PRIORITY_LOW;
  hdma_memtomem_dma2_stream0.Init.FIFOMode = DMA_FIFOMODE_ENABLE;
  hdma_memtomem_dma2_stream0.Init.FIFOThreshold = DMA_FIFO_THRESHOLD_FULL;
  hdma_memtomem_dma2_stream0.Init.MemBurst = DMA_MBURST_SINGLE;
  hdma_memtomem_dma2_stream0.Init.PeriphBurst = DMA_PBURST_SINGLE;
  if (HAL_DMA_Init(&hdma_memtomem_dma2_stream0) != HAL_OK)
  {
    Error_Handler( );
  }

  /* DMA interrupt init */
  /* DMA1_Stream1_IRQn interrupt configuration */
  HAL_NVIC_SetPriority(DMA1_Stream1_IRQn, 5, 0);
  HAL_NVIC_EnableIRQ(DMA1_Stream1_IRQn);
  /* DMA1_Stream3_IRQn interrupt configuration */
  HAL_NVIC_SetPriority(DMA1_Stream3_IRQn, 5, 0);
  HAL_NVIC_EnableIRQ(DMA1_Stream3_IRQn);
  /* DMA2_Stream3_IRQn interrupt configuration */
  HAL_NVIC_SetPriority(DMA2_Stream3_IRQn, 5, 0);
  HAL_NVIC_EnableIRQ(DMA2_Stream3_IRQn);
  /* DMA2_Stream4_IRQn interrupt configuration */
  HAL_NVIC_SetPriority(DMA2_Stream4_IRQn, 5, 0);
  HAL_NVIC_EnableIRQ(DMA2_Stream4_IRQn);
  /* DMA2_Stream7_IRQn interrupt configuration */
  HAL_NVIC_SetPriority(DMA2_Stream7_IRQn, 5, 0);
  HAL_NVIC_EnableIRQ(DMA2_Stream7_IRQn);

}

/* FMC initialization function */
static void MX_FMC_Init(void)
{

  FMC_SDRAM_TimingTypeDef SdramTiming = {0};

  /** Perform the SDRAM1 memory initialization sequence
  */
  hsdram1.Instance = FMC_SDRAM_DEVICE;
  /* hsdram1.Init */
  hsdram1.Init.SDBank = FMC_SDRAM_BANK1;
  hsdram1.Init.ColumnBitsNumber = FMC_SDRAM_COLUMN_BITS_NUM_8;
  hsdram1.Init.RowBitsNumber = FMC_SDRAM_ROW_BITS_NUM_12;
  hsdram1.Init.MemoryDataWidth = FMC_SDRAM_MEM_BUS_WIDTH_16;
  hsdram1.Init.InternalBankNumber = FMC_SDRAM_INTERN_BANKS_NUM_4;
  hsdram1.Init.CASLatency = FMC_SDRAM_CAS_LATENCY_3;
  hsdram1.Init.WriteProtection = FMC_SDRAM_WRITE_PROTECTION_DISABLE;
  hsdram1.Init.SDClockPeriod = FMC_SDRAM_CLOCK_PERIOD_2;
  hsdram1.Init.ReadBurst = FMC_SDRAM_RBURST_ENABLE;
  hsdram1.Init.ReadPipeDelay = FMC_SDRAM_RPIPE_DELAY_0;
  /* SdramTiming */
  SdramTiming.LoadToActiveDelay = 2;
  SdramTiming.ExitSelfRefreshDelay = 7;
  SdramTiming.SelfRefreshTime = 4;
  SdramTiming.RowCycleDelay = 7;
  SdramTiming.WriteRecoveryTime = 3;
  SdramTiming.RPDelay = 2;
  SdramTiming.RCDDelay = 2;

  if (HAL_SDRAM_Init(&hsdram1, &SdramTiming) != HAL_OK)
  {
    Error_Handler( );
  }

  /* USER CODE BEGIN FMC_Init 2 */
  MX_SDRAM_InitEx();
  /* USER CODE END FMC_Init 2 */
}

static void MX_GPIO_Init(void)
{
  GPIO_InitTypeDef GPIO_InitStruct = {0};

  /* GPIO Ports Clock Enable */
  __HAL_RCC_GPIOE_CLK_ENABLE();
  __HAL_RCC_GPIOC_CLK_ENABLE();
  __HAL_RCC_GPIOF_CLK_ENABLE();
  __HAL_RCC_GPIOH_CLK_ENABLE();
  __HAL_RCC_GPIOA_CLK_ENABLE();
  __HAL_RCC_GPIOB_CLK_ENABLE();
  __HAL_RCC_GPIOG_CLK_ENABLE();
  __HAL_RCC_GPIOD_CLK_ENABLE();

  /*Configure GPIO pin Output Level */
  HAL_GPIO_WritePin(GPIOE, Flash_WP_Pin|LCD_BL_CTRL_Pin, GPIO_PIN_SET);

  /*Configure GPIO pin Output Level */
  HAL_GPIO_WritePin(SPI5_CS_GPIO_Port, SPI5_CS_Pin, GPIO_PIN_RESET);

  /*Configure GPIO pin Output Level */
  HAL_GPIO_WritePin(GPIOB, USART3_DE_Pin|LCD_RST_Pin, GPIO_PIN_RESET);

  /*Configure GPIO pin Output Level */
  HAL_GPIO_WritePin(GPIOG, LTDC_DISP_Pin|GPIO_OUT_BEEP_Pin, GPIO_PIN_RESET);

  /*Configure GPIO pin Output Level */
  HAL_GPIO_WritePin(CTP_RST_GPIO_Port, CTP_RST_Pin, GPIO_PIN_SET);

  /*Configure GPIO pins : PE3 PE6 */
  GPIO_InitStruct.Pin = GPIO_PIN_3|GPIO_PIN_6;
  GPIO_InitStruct.Mode = GPIO_MODE_ANALOG;
  GPIO_InitStruct.Pull = GPIO_NOPULL;
  HAL_GPIO_Init(GPIOE, &GPIO_InitStruct);

  /*Configure GPIO pins : Flash_WP_Pin LCD_BL_CTRL_Pin */
  GPIO_InitStruct.Pin = Flash_WP_Pin|LCD_BL_CTRL_Pin;
  GPIO_InitStruct.Mode = GPIO_MODE_OUTPUT_PP;
  GPIO_InitStruct.Pull = GPIO_NOPULL;
  GPIO_InitStruct.Speed = GPIO_SPEED_FREQ_LOW;
  HAL_GPIO_Init(GPIOE, &GPIO_InitStruct);

  /*Configure GPIO pins : PC13 PC4 PC5 */
  GPIO_InitStruct.Pin = GPIO_PIN_13|GPIO_PIN_4|GPIO_PIN_5;
  GPIO_InitStruct.Mode = GPIO_MODE_ANALOG;
  GPIO_InitStruct.Pull = GPIO_NOPULL;
  HAL_GPIO_Init(GPIOC, &GPIO_InitStruct);

  /*Configure GPIO pin : SPI5_CS_Pin */
  GPIO_InitStruct.Pin = SPI5_CS_Pin;
  GPIO_InitStruct.Mode = GPIO_MODE_OUTPUT_PP;
  GPIO_InitStruct.Pull = GPIO_NOPULL;
  GPIO_InitStruct.Speed = GPIO_SPEED_FREQ_HIGH;
  HAL_GPIO_Init(SPI5_CS_GPIO_Port, &GPIO_InitStruct);

  /*Configure GPIO pins : PA0 PA9 PA11 PA12
                           PA15 */
  GPIO_InitStruct.Pin = GPIO_PIN_0|GPIO_PIN_9|GPIO_PIN_11|GPIO_PIN_12
                          |GPIO_PIN_15;
  GPIO_InitStruct.Mode = GPIO_MODE_ANALOG;
  GPIO_InitStruct.Pull = GPIO_NOPULL;
  HAL_GPIO_Init(GPIOA, &GPIO_InitStruct);

  /*Configure GPIO pins : PB12 PB3 PB4 PB5
                           PB7 */
  GPIO_InitStruct.Pin = GPIO_PIN_12|GPIO_PIN_3|GPIO_PIN_4|GPIO_PIN_5
                          |GPIO_PIN_7;
  GPIO_InitStruct.Mode = GPIO_MODE_ANALOG;
  GPIO_InitStruct.Pull = GPIO_NOPULL;
  HAL_GPIO_Init(GPIOB, &GPIO_InitStruct);

  /*Configure GPIO pin : PB13 */
  GPIO_InitStruct.Pin = GPIO_PIN_13;
  GPIO_InitStruct.Mode = GPIO_MODE_AF_PP;
  GPIO_InitStruct.Pull = GPIO_NOPULL;
  GPIO_InitStruct.Speed = GPIO_SPEED_FREQ_VERY_HIGH;
  GPIO_InitStruct.Alternate = GPIO_AF9_CAN2;
  HAL_GPIO_Init(GPIOB, &GPIO_InitStruct);

  /*Configure GPIO pins : USART3_DE_Pin LCD_RST_Pin */
  GPIO_InitStruct.Pin = USART3_DE_Pin|LCD_RST_Pin;
  GPIO_InitStruct.Mode = GPIO_MODE_OUTPUT_PP;
  GPIO_InitStruct.Pull = GPIO_NOPULL;
  GPIO_InitStruct.Speed = GPIO_SPEED_FREQ_LOW;
  HAL_GPIO_Init(GPIOB, &GPIO_InitStruct);

  /*Configure GPIO pins : LTDC_DISP_Pin GPIO_OUT_BEEP_Pin */
  GPIO_InitStruct.Pin = LTDC_DISP_Pin|GPIO_OUT_BEEP_Pin;
  GPIO_InitStruct.Mode = GPIO_MODE_OUTPUT_PP;
  GPIO_InitStruct.Pull = GPIO_NOPULL;
  GPIO_InitStruct.Speed = GPIO_SPEED_FREQ_LOW;
  HAL_GPIO_Init(GPIOG, &GPIO_InitStruct);

  /*Configure GPIO pin : PG3 */
  GPIO_InitStruct.Pin = GPIO_PIN_3;
  GPIO_InitStruct.Mode = GPIO_MODE_ANALOG;
  GPIO_InitStruct.Pull = GPIO_NOPULL;
  HAL_GPIO_Init(GPIOG, &GPIO_InitStruct);

  /*Configure GPIO pin : CTP_RST_Pin */
  GPIO_InitStruct.Pin = CTP_RST_Pin;
  GPIO_InitStruct.Mode = GPIO_MODE_OUTPUT_PP;
  GPIO_InitStruct.Pull = GPIO_NOPULL;
  GPIO_InitStruct.Speed = GPIO_SPEED_FREQ_LOW;
  HAL_GPIO_Init(CTP_RST_GPIO_Port, &GPIO_InitStruct);

  /*Configure GPIO pin : CTP_INT_Pin */
  GPIO_InitStruct.Pin = CTP_INT_Pin;
  GPIO_InitStruct.Mode = GPIO_MODE_IT_RISING;
  GPIO_InitStruct.Pull = GPIO_NOPULL;
  HAL_GPIO_Init(CTP_INT_GPIO_Port, &GPIO_InitStruct);

  /*Configure GPIO pins : PD4 PD5 PD7 */
  GPIO_InitStruct.Pin = GPIO_PIN_4|GPIO_PIN_5|GPIO_PIN_7;
  GPIO_InitStruct.Mode = GPIO_MODE_ANALOG;
  GPIO_InitStruct.Pull = GPIO_NOPULL;
  HAL_GPIO_Init(GPIOD, &GPIO_InitStruct);

}

/* USER CODE BEGIN 4 */
void MX_SDRAM_InitEx(void)
{

  /* For SDRAM initial */
  #define REFRESH_COUNT        1386
  #define SDRAM_TIMEOUT                            ((uint32_t)0xFFFF)
  #define SDRAM_MODEREG_BURST_LENGTH_1             ((uint16_t)0x0000)
  #define SDRAM_MODEREG_BURST_LENGTH_2             ((uint16_t)0x0001)
  #define SDRAM_MODEREG_BURST_LENGTH_4             ((uint16_t)0x0002)
  #define SDRAM_MODEREG_BURST_LENGTH_8             ((uint16_t)0x0004)
  #define SDRAM_MODEREG_BURST_TYPE_SEQUENTIAL      ((uint16_t)0x0000)
  #define SDRAM_MODEREG_BURST_TYPE_INTERLEAVED     ((uint16_t)0x0008)
  #define SDRAM_MODEREG_CAS_LATENCY_2              ((uint16_t)0x0020)
  #define SDRAM_MODEREG_CAS_LATENCY_3              ((uint16_t)0x0030)
  #define SDRAM_MODEREG_OPERATING_MODE_STANDARD    ((uint16_t)0x0000)
  #define SDRAM_MODEREG_WRITEBURST_MODE_PROGRAMMED ((uint16_t)0x0000)
  #define SDRAM_MODEREG_WRITEBURST_MODE_SINGLE     ((uint16_t)0x0200)

  __IO uint32_t tmpmrd = 0;
  FMC_SDRAM_CommandTypeDef Command;

  /* Step 1: Configure a clock configuration enable command */
  Command.CommandMode = FMC_SDRAM_CMD_CLK_ENABLE;
  Command.CommandTarget = FMC_SDRAM_CMD_TARGET_BANK1;
  Command.AutoRefreshNumber = 1;
  Command.ModeRegisterDefinition = 0;

  /* Send the command */
  HAL_SDRAM_SendCommand(&hsdram1, &Command, SDRAM_TIMEOUT);

  /* Step 2: Insert 100 us minimum delay */
  /* Inserted delay is equal to 1 ms due to systick time base unit (ms) */
  HAL_Delay(1);

  /* Step 3: Configure a PALL (precharge all) command */
  Command.CommandMode = FMC_SDRAM_CMD_PALL;
  Command.CommandTarget = FMC_SDRAM_CMD_TARGET_BANK1;
  Command.AutoRefreshNumber = 1;
  Command.ModeRegisterDefinition = 0;

  /* Send the command */
  HAL_SDRAM_SendCommand(&hsdram1, &Command, SDRAM_TIMEOUT);

  /* Step 4: Configure an Auto Refresh command */
  Command.CommandMode = FMC_SDRAM_CMD_AUTOREFRESH_MODE;
  Command.CommandTarget = FMC_SDRAM_CMD_TARGET_BANK1;
  Command.AutoRefreshNumber = 8;
  Command.ModeRegisterDefinition = 0;

  /* Send the command */
  HAL_SDRAM_SendCommand(&hsdram1, &Command, SDRAM_TIMEOUT);

  /* Step 5: Program the external memory mode register */
  /*Todo Check CAS_LATENCY value*/

  tmpmrd = (uint32_t) SDRAM_MODEREG_BURST_LENGTH_1
      |\
  SDRAM_MODEREG_BURST_TYPE_SEQUENTIAL |\
  SDRAM_MODEREG_CAS_LATENCY_3
      |\
  SDRAM_MODEREG_OPERATING_MODE_STANDARD
      |\
  SDRAM_MODEREG_WRITEBURST_MODE_SINGLE;

  Command.CommandMode = FMC_SDRAM_CMD_LOAD_MODE;
  Command.CommandTarget = FMC_SDRAM_CMD_TARGET_BANK1;
  Command.AutoRefreshNumber = 1;
  Command.ModeRegisterDefinition = tmpmrd;

  /* Send the command */
  HAL_SDRAM_SendCommand(&hsdram1, &Command, SDRAM_TIMEOUT);

  /* Step 6: Set the refresh rate counter */
  /* Set the device refresh rate */
  HAL_SDRAM_ProgramRefreshRate(&hsdram1, REFRESH_COUNT);
}
/* USER CODE END 4 */

__weak void TouchGFX_Task(void *argument)
{
  /* USER CODE BEGIN 5 */
  MX_TouchGFX_Process();
  /* Infinite loop */
  for(;;)
  {
    osDelay(1);
  }
  /* USER CODE END 5 */
}

/* MPU Configuration */

void MPU_Config(void)
{
  MPU_Region_InitTypeDef MPU_InitStruct = {0};

  /* Disables the MPU */
  HAL_MPU_Disable();
  /** Initializes and configures the Region and the memory to be protected
  */
  MPU_InitStruct.Enable = MPU_REGION_ENABLE;
  MPU_InitStruct.Number = MPU_REGION_NUMBER0;
  MPU_InitStruct.BaseAddress = 0xC0000000;
  MPU_InitStruct.Size = MPU_REGION_SIZE_8MB;
  MPU_InitStruct.SubRegionDisable = 0x0;
  MPU_InitStruct.TypeExtField = MPU_TEX_LEVEL0;
  MPU_InitStruct.AccessPermission = MPU_REGION_FULL_ACCESS;
  MPU_InitStruct.DisableExec = MPU_INSTRUCTION_ACCESS_DISABLE;
  MPU_InitStruct.IsShareable = MPU_ACCESS_NOT_SHAREABLE;
  MPU_InitStruct.IsCacheable = MPU_ACCESS_CACHEABLE;
  MPU_InitStruct.IsBufferable = MPU_ACCESS_NOT_BUFFERABLE;

  HAL_MPU_ConfigRegion(&MPU_InitStruct);
  /* Enables the MPU */
  HAL_MPU_Enable(MPU_PRIVILEGED_DEFAULT);

}
void HAL_TIM_PeriodElapsedCallback(TIM_HandleTypeDef *htim)
{
  if (htim->Instance == TIM5) {
    HAL_IncTick();
  }
}

void Error_Handler(void)
{
  /* USER CODE BEGIN Error_Handler_Debug */
  /* User can add his own implementation to report the HAL error return state */
  while(1);
  /* USER CODE END Error_Handler_Debug */
}

/************************ (C) COPYRIGHT STMicroelectronics *****END OF FILE****/

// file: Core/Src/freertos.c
/* USER CODE BEGIN Header */
/**
  ******************************************************************************
  * File Name          : freertos.c
  * Description        : Code for freertos applications
  ******************************************************************************
  * @attention
  *
  * <h2><center>&copy; Copyright (c) 2020 STMicroelectronics.
  * All rights reserved.</center></h2>
  *
  * This software component is licensed by ST under Ultimate Liberty license
  * SLA0044, the "License"; You may not use this file except in compliance with
  * the License. You may obtain a copy of the License at:
  *                             www.st.com/SLA0044
  *
  ******************************************************************************
  */
/* USER CODE END Header */

#include "FreeRTOS.h"
#include "task.h"
#include "main.h"

/* Hook prototypes */
void vApplicationIdleHook(void);

/* USER CODE BEGIN 2 */
__weak void vApplicationIdleHook( void )
{
   /* vApplicationIdleHook() will only be called if configUSE_IDLE_HOOK is set
   to 1 in FreeRTOSConfig.h. It will be called on each iteration of the idle
   task. It is essential that code added to this hook function never attempts
   to block in any way (for example, call xQueueReceive() with a block time
   specified, or call vTaskDelay()). If the application makes use of the
   vTaskDelete() API function (as this demo application does) then it is also
   important that vApplicationIdleHook() is permitted to return to its calling
   function, because it is the responsibility of the idle task to clean up
   memory allocated by the kernel to any task that has since been deleted. */
}
/* USER CODE END 2 */

/************************ (C) COPYRIGHT STMicroelectronics *****END OF FILE****/
